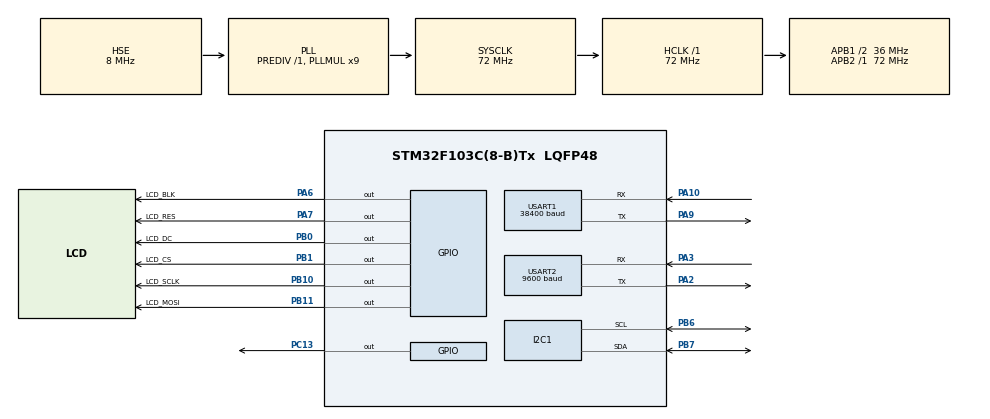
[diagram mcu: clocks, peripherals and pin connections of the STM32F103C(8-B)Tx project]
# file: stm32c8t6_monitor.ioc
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I2C1.I2C_Mode=I2C_Fast
Mcu.Family=STM32F1
Mcu.Name=STM32F103C(8-B)Tx
Mcu.Package=LQFP48
NVIC.I2C1_ER_IRQn=true\:0\:0\:false\:false\:true\:true\:true\:true
NVIC.I2C1_EV_IRQn=true\:0\:0\:false\:false\:true\:true\:true\:true
NVIC.PriorityGroup=NVIC_PRIORITYGROUP_4
NVIC.TIM1_TRG_COM_IRQn=true\:0\:0\:false\:false\:true\:true\:true\:true
NVIC.TIM1_UP_IRQn=true\:0\:0\:true\:false\:true\:true\:true\:true
NVIC.TIM2_IRQn=true\:0\:0\:true\:false\:true\:true\:true\:true
NVIC.TIM3_IRQn=true\:0\:0\:true\:false\:true\:true\:true\:true
NVIC.USART1_IRQn=true\:0\:0\:true\:false\:true\:true\:true\:true
NVIC.USART2_IRQn=true\:0\:0\:true\:false\:true\:true\:true\:true
PA10.Mode=Asynchronous
PA10.Signal=USART1_RX
PA13.Mode=Serial_Wire
PA13.Signal=SYS_JTMS-SWDIO
PA14.Mode=Serial_Wire
PA14.Signal=SYS_JTCK-SWCLK
PA2.Mode=Asynchronous
PA2.Signal=USART2_TX
PA3.Mode=Asynchronous
PA3.Signal=USART2_RX
PA6.GPIO_Label=LCD_BLK
PA6.GPIO_Speed=GPIO_SPEED_FREQ_HIGH
PA6.Signal=GPIO_Output
PA7.GPIO_Label=LCD_RES
PA7.GPIO_Speed=GPIO_SPEED_FREQ_HIGH
PA7.Signal=GPIO_Output
PA9.Mode=Asynchronous
PA9.Signal=USART1_TX
PB0.GPIO_Label=LCD_DC
PB0.GPIO_Speed=GPIO_SPEED_FREQ_HIGH
PB0.Signal=GPIO_Output
PB1.GPIO_Label=LCD_CS
PB1.GPIO_Speed=GPIO_SPEED_FREQ_HIGH
PB1.Signal=GPIO_Output
PB10.GPIO_Label=LCD_SCLK
PB10.GPIO_Speed=GPIO_SPEED_FREQ_HIGH
PB10.Signal=GPIO_Output
PB11.GPIO_Label=LCD_MOSI
PB11.GPIO_Speed=GPIO_SPEED_FREQ_HIGH
PB11.Signal=GPIO_Output
PB6.Mode=I2C
PB6.Signal=I2C1_SCL
PB7.Mode=I2C
PB7.Signal=I2C1_SDA
PC13-TAMPER-RTC.GPIO_Speed=GPIO_SPEED_FREQ_HIGH
PC13-TAMPER-RTC.Signal=GPIO_Output
PC14-OSC32_IN.Mode=LSE-External-Oscillator
PC14-OSC32_IN.Signal=RCC_OSC32_IN
PC15-OSC32_OUT.Mode=LSE-External-Oscillator
PC15-OSC32_OUT.Signal=RCC_OSC32_OUT
PD0-OSC_IN.Mode=HSE-External-Oscillator
PD0-OSC_IN.Signal=RCC_OSC_IN
PD1-OSC_OUT.Mode=HSE-External-Oscillator
PD1-OSC_OUT.Signal=RCC_OSC_OUT
ProjectManager.HeapSize=0x200
ProjectManager.StackSize=0x400
ProjectManager.TargetToolchain=STM32CubeIDE
RCC.AHBFreq_Value=72000000
RCC.APB1CLKDivider=RCC_HCLK_DIV2
RCC.APB1Freq_Value=36000000
RCC.APB1TimFreq_Value=72000000
RCC.APB2Freq_Value=72000000
RCC.APB2TimFreq_Value=72000000
RCC.HCLKFreq_Value=72000000
RCC.PLLMUL=RCC_PLL_MUL9
RCC.PLLSourceVirtual=RCC_PLLSOURCE_HSE
RCC.SYSCLKFreq_VALUE=72000000
RCC.SYSCLKSource=RCC_SYSCLKSOURCE_PLLCLK
RCC.USBFreq_Value=72000000
TIM1.Period=3500-1
TIM1.Prescaler=7200-1
TIM2.Period=10-1
TIM2.Prescaler=7200-1
TIM3.Period=100-1
TIM3.Prescaler=7200-1
USART1.BaudRate=38400
USART1.VirtualMode=VM_ASYNC
USART2.BaudRate=9600
USART2.VirtualMode=VM_ASYNC
VP_RTC_VS_RTC_Activate.Mode=RTC_Enabled
VP_TIM1_VS_ClockSourceINT.Mode=Internal
VP_TIM2_VS_ClockSourceINT.Mode=Internal
VP_TIM3_VS_ClockSourceINT.Mode=Internal
board=custom

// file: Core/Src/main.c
/* USER CODE BEGIN Header */
/**
  ******************************************************************************
  * @file           : main.c
  * @brief          : Main program body
  ******************************************************************************
  * @attention
  *
  * Copyright (c) 2024 STMicroelectronics.
  * All rights reserved.
  *
  * This software is licensed under terms that can be found in the LICENSE file
  * in the root directory of this software component.
  * If no LICENSE file comes with this software, it is provided AS-IS.
  *
  ******************************************************************************
  */
/* USER CODE END Header */
#include "main.h"
#include "ATK_MPU6050_SoftwareDriver/atk_ms6050.h"
#include "i2c.h"
#include "rtc.h"
#include "tim.h"
#include "usart.h"
#include "gpio.h"

/* USER CODE BEGIN Includes */
#include "LCD_Init.h"
#include "LCD.h"
#include "stm32f1xx_hal.h"
#include "LoopProgram.h"
#include "HealthMonitor.h"
#include <BLE.h>
#include <stdint.h>
/* USER CODE END Includes */

void SystemClock_Config(void);

int main(void)
{

  /* MCU Configuration--------------------------------------------------------*/

  /* Reset of all peripherals, Initializes the Flash interface and the Systick. */
  HAL_Init();

  /* Configure the system clock */
  SystemClock_Config();

  /* Initialize all configured peripherals */
  MX_GPIO_Init();
  MX_RTC_Init();
  MX_TIM1_Init();
  MX_TIM2_Init();
  MX_TIM3_Init();
  MX_USART1_UART_Init();
  MX_I2C1_Init();
  MX_USART2_UART_Init();
  /* USER CODE BEGIN 2 */
    BLE_Init();
    // LoopProgram_WatchDog_Set(TRUE);
    LCD_Init();
    LCD_Fill(0, 0, LCD_W, LCD_H, WHITE);
    my_mpu6050_init();
    HealthMonitor_Init();
    LoopProgram_Start();
    // LoopProgram_WatchDog_Set(TRUE);
    // uint16_t progress = 0;
  /* USER CODE END 2 */

  /* Infinite loop */
  /* USER CODE BEGIN WHILE */
    while (/*MPU6050_Init(&hi2c1) ==*/ 1)
    {
    /* USER CODE END WHILE */

    /* USER CODE BEGIN 3 */
        LoopProgram_Main();
    }
  /* USER CODE END 3 */
}

void SystemClock_Config(void)
{
  RCC_OscInitTypeDef RCC_OscInitStruct = {0};
  RCC_ClkInitTypeDef RCC_ClkInitStruct = {0};
  RCC_PeriphCLKInitTypeDef PeriphClkInit = {0};

  /** Initializes the RCC Oscillators according to the specified parameters
  * in the RCC_OscInitTypeDef structure.
  */
  RCC_OscInitStruct.OscillatorType = RCC_OSCILLATORTYPE_LSI|RCC_OSCILLATORTYPE_HSE;
  RCC_OscInitStruct.HSEState = RCC_HSE_ON;
  RCC_OscInitStruct.HSEPredivValue = RCC_HSE_PREDIV_DIV1;
  RCC_OscInitStruct.HSIState = RCC_HSI_ON;
  RCC_OscInitStruct.LSIState = RCC_LSI_ON;
  RCC_OscInitStruct.PLL.PLLState = RCC_PLL_ON;
  RCC_OscInitStruct.PLL.PLLSource = RCC_PLLSOURCE_HSE;
  RCC_OscInitStruct.PLL.PLLMUL = RCC_PLL_MUL9;
  if (HAL_RCC_OscConfig(&RCC_OscInitStruct) != HAL_OK)
  {
    Error_Handler();
  }

  /** Initializes the CPU, AHB and APB buses clocks
  */
  RCC_ClkInitStruct.ClockType = RCC_CLOCKTYPE_HCLK|RCC_CLOCKTYPE_SYSCLK
                              |RCC_CLOCKTYPE_PCLK1|RCC_CLOCKTYPE_PCLK2;
  RCC_ClkInitStruct.SYSCLKSource = RCC_SYSCLKSOURCE_PLLCLK;
  RCC_ClkInitStruct.AHBCLKDivider = RCC_SYSCLK_DIV1;
  RCC_ClkInitStruct.APB1CLKDivider = RCC_HCLK_DIV2;
  RCC_ClkInitStruct.APB2CLKDivider = RCC_HCLK_DIV1;

  if (HAL_RCC_ClockConfig(&RCC_ClkInitStruct, FLASH_LATENCY_2) != HAL_OK)
  {
    Error_Handler();
  }
  PeriphClkInit.PeriphClockSelection = RCC_PERIPHCLK_RTC;
  PeriphClkInit.RTCClockSelection = RCC_RTCCLKSOURCE_LSI;
  if (HAL_RCCEx_PeriphCLKConfig(&PeriphClkInit) != HAL_OK)
  {
    Error_Handler();
  }
}

void Error_Handler(void)
{
    __disable_irq();
    while (1)
    {
    }
}
